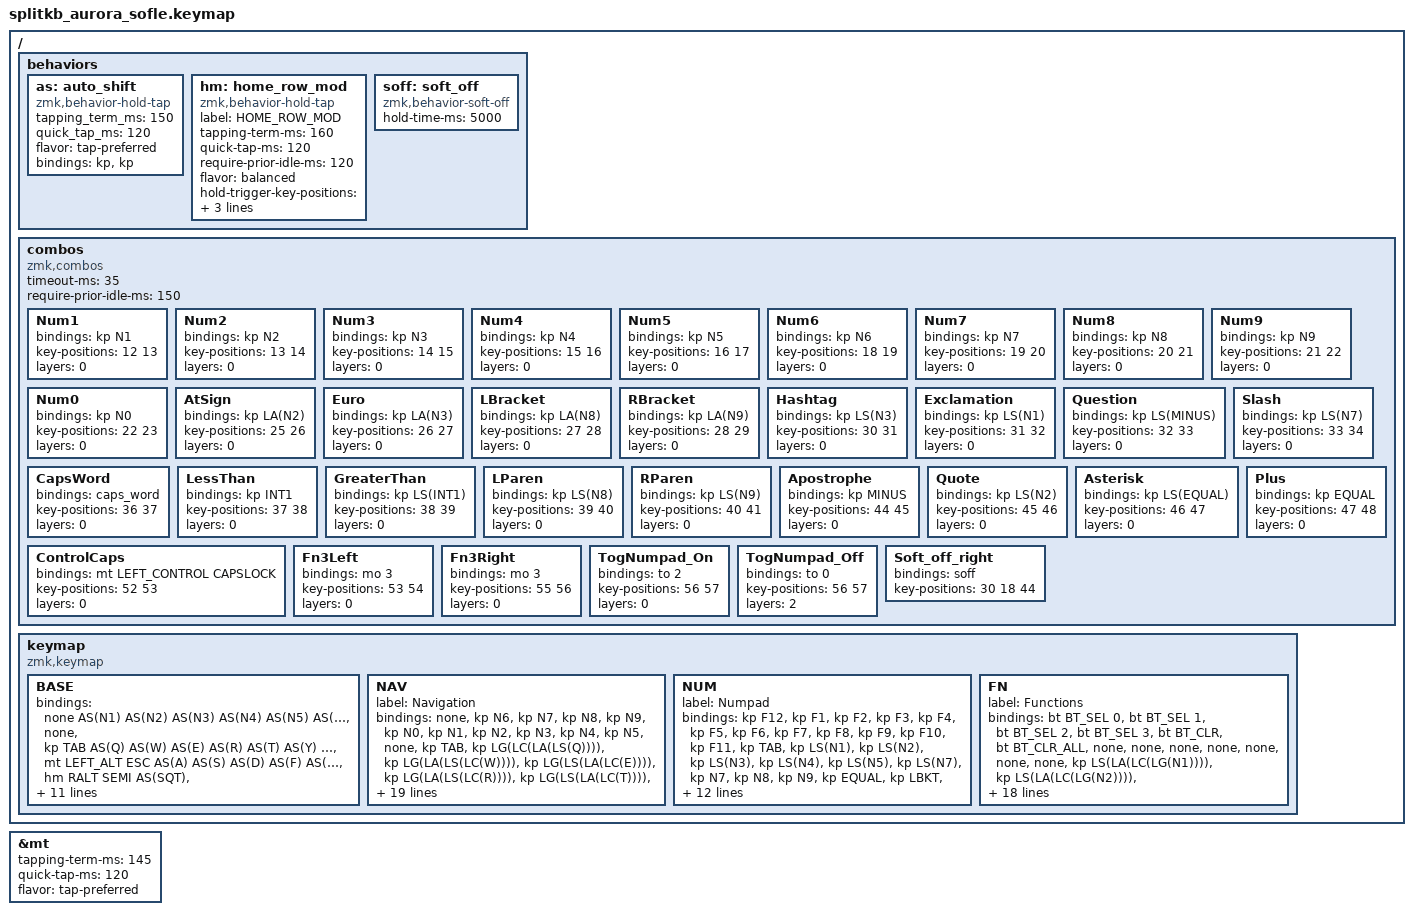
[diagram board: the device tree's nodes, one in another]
/*
 * Copyright (c) 2026 The ZMK Contributors
 * Keymap designed by Raphael Stanzani
 * SPDX-License-Identifier: MIT
 */

#include <behaviors.dtsi>
#include <dt-bindings/zmk/bt.h>
#include <dt-bindings/zmk/keys.h>
#include <dt-bindings/zmk/mouse.h>

/* Not being used:
* #include <dt-bindings/zmk/pointing.h>
* #define ZMK_POINTING_DEFAULT_MOVE_VAL 1500  // default: 600
* #define ZMK_POINTING_DEFAULT_SCRL_VAL 20    // default: 10
*/

#define AS(keycode) &as LS(keycode) keycode     // Autoshift Macro

&mt {
    tapping-term-ms = <145>;
    quick-tap-ms = <120>;
    flavor = "tap-preferred";
};

/ {
    behaviors {
        as: auto_shift {
            compatible = "zmk,behavior-hold-tap";
            #binding-cells = <2>;
            tapping_term_ms = <150>;
            quick_tap_ms = <120>;
            flavor = "tap-preferred";
            bindings = <&kp>, <&kp>;
        };

        hm: home_row_mod {
            compatible = "zmk,behavior-hold-tap";
            label = "HOME_ROW_MOD";
            #binding-cells = <2>;
            tapping-term-ms = <160>;
            quick-tap-ms = <120>;
            require-prior-idle-ms = <120>;
            flavor = "balanced";

        hold-trigger-key-positions = <
            /* top row */
            0 1 2 3 4 5 6 7 8 9 10 11
            /* bottom row */
            36 37 38 39 40 41 42 43 44 45 46 47 48 49
            /* thumbs */
            50 51 52 53 54 55 56 57 58 59
        >;
        hold-trigger-on-release;
        bindings = <&kp>, <&kp>;
        };

        soff: soft_off {
            compatible = "zmk,behavior-soft-off";
            #binding-cells = <0>;
            // split-peripheral-off-on-press;
            hold-time-ms = <5000>; // Only turn off it the key is held for 5 seconds or longer.
        };
    };

    combos {
        compatible = "zmk,combos";
        timeout-ms = <35>;
        require-prior-idle-ms = <150>;

        Num1 {
            bindings = <&kp N1>;
            key-positions = <12 13>;
            layers = <0>;
        };

        Num2 {
            bindings = <&kp N2>;
            key-positions = <13 14>;
            layers = <0>;
        };

        Num3 {
            bindings = <&kp N3>;
            key-positions = <14 15>;
            layers = <0>;
        };

        Num4 {
            bindings = <&kp N4>;
            key-positions = <15 16>;
            layers = <0>;
        };

        Num5 {
            bindings = <&kp N5>;
            key-positions = <16 17>;
            layers = <0>;
        };

        Num6 {
            bindings = <&kp N6>;
            key-positions = <18 19>;
            layers = <0>;
        };

        Num7 {
            bindings = <&kp N7>;
            key-positions = <19 20>;
            layers = <0>;
        };

        Num8 {
            bindings = <&kp N8>;
            key-positions = <20 21>;
            layers = <0>;
        };

        Num9 {
            bindings = <&kp N9>;
            key-positions = <21 22>;
            layers = <0>;
        };

        Num0 {
            bindings = <&kp N0>;
            key-positions = <22 23>;
            layers = <0>;
        };

        AtSign {
            bindings = <&kp LA(N2)>;
            key-positions = <25 26>;
            layers = <0>;
        };

        Euro {
            bindings = <&kp LA(N3)>;
            key-positions = <26 27>;
            layers = <0>;
        };

        LBracket {
            bindings = <&kp LA(N8)>;
            key-positions = <27 28>;
            layers = <0>;
        };

        RBracket {
            bindings = <&kp LA(N9)>;
            key-positions = <28 29>;
            layers = <0>;
        };

        Hashtag {
            bindings = <&kp LS(N3)>;
            key-positions = <30 31>;
            layers = <0>;
        };

        Exclamation {
            bindings = <&kp LS(N1)>;
            key-positions = <31 32>;
            layers = <0>;
        };

        Question {
            bindings = <&kp LS(MINUS)>;
            key-positions = <32 33>;
            layers = <0>;
        };

        Slash {
            bindings = <&kp LS(N7)>;
            key-positions = <33 34>;
            layers = <0>;
        };

        CapsWord {
            bindings = <&caps_word>;
            key-positions = <36 37>;
            layers = <0>;
        };

        LessThan {
            bindings = <&kp INT1>;
            key-positions = <37 38>;
            layers = <0>;
        };

        GreaterThan {
            bindings = <&kp LS(INT1)>;
            key-positions = <38 39>;
            layers = <0>;
        };

        LParen {
            bindings = <&kp LS(N8)>;
            key-positions = <39 40>;
            layers = <0>;
        };

        RParen {
            bindings = <&kp LS(N9)>;
            key-positions = <40 41>;
            layers = <0>;
        };

        Apostrophe {
            bindings = <&kp MINUS>;
            key-positions = <44 45>;
            layers = <0>;
        };

        Quote {
            bindings = <&kp LS(N2)>;
            key-positions = <45 46>;
            layers = <0>;
        };

        Asterisk {
            bindings = <&kp LS(EQUAL)>;
            key-positions = <46 47>;
            layers = <0>;
        };

        Plus {
            bindings = <&kp EQUAL>;
            key-positions = <47 48>;
            layers = <0>;
        };

        ControlCaps {
            bindings = <&mt LEFT_CONTROL CAPSLOCK>;
            key-positions = <52 53>;
            layers = <0>;
        };

        Fn3Left {
            bindings = <&mo 3>;
            key-positions = <53 54>;
            layers = <0>;
        };

        Fn3Right {
            bindings = <&mo 3>;
            key-positions = <55 56>;
            layers = <0>;
        };

        TogNumpad_On {
            bindings = <&to 2>;
            key-positions = <56 57>;
            layers = <0>;
        };

        TogNumpad_Off {
            bindings = <&to 0>;
            key-positions = <56 57>;
            layers = <2>;
        };

          Soft_off_right {
            bindings = <&soff>;
            key-positions = <30 18 44>;
        };
    };

    keymap {
        compatible = "zmk,keymap";

        BASE {
            bindings = <
&none       AS(N1)      AS(N2)       AS(N3)       AS(N4)        AS(N5)                                                 AS(N6)  AS(N7)       AS(N8)      AS(N9)       AS(N0)          &none
&kp TAB     AS(Q)       AS(W)        AS(E)        AS(R)         AS(T)                                                  AS(Y)   AS(U)        AS(I)       AS(O)        AS(P)           AS(RIGHT_BRACKET)
&mt LEFT_ALT ESC  AS(A)    AS(S)        AS(D)        AS(F)         AS(G)                                                  AS(H)   AS(J)        AS(K)       AS(L)        &hm RALT SEMI   AS(SQT)
&kp LSHIFT AS(Z)       AS(X)        AS(C)        AS(V)         AS(B)       &none                       &none       AS(N)   AS(M)        AS(COMMA)   AS(DOT)      AS(SLASH)    &mt RIGHT_SHIFT ENTER
                   &kp C_VOL_DN  &lt 3 C_VOL_UP  &mt LC(LA(LS(LEFT_GUI))) F2  &mt LGUI SPACE  &lt 2 ENTER    &mt RGUI BACKSPACE  &lt 1 SPACE  &mt RS(RC(RA(RIGHT_GUI))) DEL  &lt 3 C_BRI_INC  &kp C_BRI_DEC
            >;

            sensor-bindings = 
                <&inc_dec_kp DOWN UP>,
                <&inc_dec_kp RIGHT LEFT>;
        };

        NAV {
            label = "Navigation";
            bindings = <
&none          &kp N6                 &kp N7                 &kp N8                 &kp N9                 &kp N0                                               &kp N1                 &kp N2         &kp N3            &kp N4            &kp N5             &none
&kp TAB        &kp LG(LC(LA(LS(Q))))  &kp LG(LA(LS(LC(W))))  &kp LG(LS(LA(LC(E))))  &kp LG(LA(LS(LC(R))))  &kp LG(LS(LA(LC(T))))                                &kp RG(B)              &kp RG(I)      &kp UP            &kp LC(LS(UP))    &kp LC(LS(RIGHT))  &kp LG(BACKSPACE)
&mt LEFT_ALT ESC  &kp LCTRL           &kp LEFT_ALT           &kp LEFT_GUI           &kp LEFT_SHIFT         &kp LG(LS(LA(LC(G))))                                &kp LS(LA(LC(LG(H))))  &kp LEFT       &kp DOWN          &kp RIGHT         &kp RG(L)          &none
&kp LSHIFT     &kp LG(LS(LA(LC(Z))))  &kp LG(LA(LS(LC(X))))  &kp LG(LA(LS(LC(C))))  &kp LG(LA(LS(LC(V))))  &kp LG(LA(LS(LC(B))))  &trans       &trans           &kp LG(K)              &kp LG(Z)      &kp LG(C)         &kp LG(V)         &kp RG(X)          &mt RSHIFT ENTER
                                      &kp K_MUTE             &kp LS(LG(M))          &mt LC(LA(LS(LEFT_GUI))) F2    &mt LEFT_GUI SPACE     &lt 3 ENTER    &lt 3 BACKSPACE  &kp SPACE            &kp LC(LS(Q))  &kp LC(LS(DOWN))  &kp LC(LS(LEFT))
            >;

            sensor-bindings =
                <&inc_dec_kp LA(LS(DOWN)) LA(LS(UP))>,
                <&inc_dec_kp LA(LS(RIGHT)) LA(LS(LEFT))>;

        };

        NUM {
            label = "Numpad";
            bindings = <
&kp F12               &kp F1      &kp F2      &kp F3      &kp F4                       &kp F5                                         &kp F6         &kp F7      &kp F8     &kp F9      &kp F10        &kp F11
&kp TAB               &kp LS(N1)  &kp LS(N2)  &kp LS(N3)  &kp LS(N4)                   &kp LS(N5)                                     &kp LS(N7)     &kp N7      &kp N8     &kp N9      &kp EQUAL      &kp LBKT
&mt LEFT_ALT ESC      &kp LA(N2)  &kp LA(N3)  &kp LGUI    &kp LEFT_SHIFT               &kp LS(NUHS)                                   &kp LS(EQUAL)  &kp N4      &kp N5     &kp N6      &kp LA(EQUAL)  &kp NON_US_HASH
&kp LSHIFT            &kp LS(N6)  &kp LA(N3)  &kp LS(N8)  &kp LS(N9)                   &kp LS(N0)    &trans            &trans         &kp N0         &kp N1      &kp N2     &kp N3      &kp FSLH       &mt RIGHT_SHIFT ENTER
                                  &kp NUBS    &kp F4      &mt LC(LA(LS(LEFT_GUI))) F2  &kp SPACE     &mt LGUI ENTER    &kp BACKSPACE  &kp SPACE      &kp LS(N0)  &kp COMMA  &kp PERIOD
            >;

            sensor-bindings =
                <&inc_dec_kp LA(DOWN) RA(UP)>,
                <&inc_dec_kp LA(RIGHT) LA(LEFT)>;
        };

        FN {
            label = "Functions";
            bindings = <
&bt BT_SEL 0  &bt BT_SEL 1            &bt BT_SEL 2            &bt BT_SEL 3            &bt BT_CLR              &bt BT_CLR_ALL                            &none           &none          &none          &none          &none          &none
&none         &kp LS(LA(LC(LG(N1))))  &kp LS(LA(LC(LG(N2))))  &kp LS(LA(LC(LG(N3))))  &kp LS(LA(LC(LG(N4))))  &kp LS(LA(LC(LG(N5))))                    &kp LS(LC(N1))  &kp LS(LC(W))  &kp LS(LC(E))  &kp LS(LC(R))  &kp LS(LC(T))  &kp LS(LC(N3))
&none         &kp LS(LA(LC(LG(N6))))  &kp LS(LA(LC(LG(N7))))  &kp LS(LA(LC(LG(N8))))  &kp LS(LA(LC(LG(N9))))  &kp LS(LA(LC(LG(N0))))                    &kp LS(LC(N2))  &kp LS(LC(S))  &kp LS(LC(D))  &kp LS(LC(F))  &kp LS(LC(G))  &kp LS(LC(N4))
&none         &none                   &kp C_PREVIOUS          &kp C_PLAY_PAUSE        &kp C_NEXT              &none                   &trans    &trans  &kp LS(LC(Z))   &kp LS(LC(X))  &kp LS(LC(C))  &kp LS(LC(V))  &kp LS(LC(B))  &kp LS(LC(N5))
                                      &kp C_VOL_DN            &kp C_VOL_UP            &none                   &none                   &none     &none   &none           &none          &kp C_BRI_INC  &kp C_BRI_DEC
            >;
        };
    };
};
